# PRU_ICSSG0_PR1_ICSS_INTC_INTC_SLV_local register map
Vendor: Texas Instruments
Peripheral module from a debugger description file (folder am65x).
Registers are 32-bit, read-write, reset 0x0 unless marked. A register's access mark holds for its fields unless they carry their own. Offsets are as the file gives them; lines under a group give offsets from that group; [hi:lo] are bit positions; {n}, {i} and the like mark numbered series; 'fields as' and 'values as' point back to an identical list; <NAME> marks a mode.

## PRU_ICSSG0_PR1_ICSS_INTC_INTC_SLV
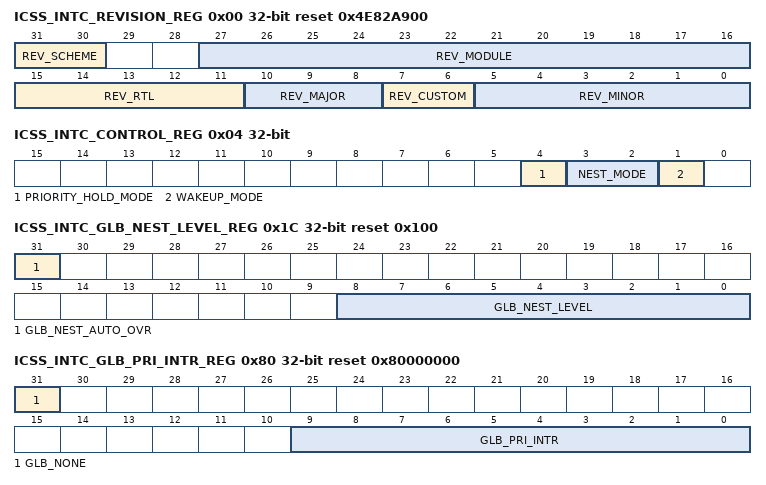
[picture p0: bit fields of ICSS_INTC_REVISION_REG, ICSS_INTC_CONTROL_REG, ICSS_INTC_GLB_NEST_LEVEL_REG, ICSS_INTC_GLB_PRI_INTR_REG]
0x00 ICSS_INTC_REVISION_REG ro reset 0x4E82A900 — Revision Register
  [31:30] REV_SCHEME — Scheme
  [27:16] REV_MODULE — Module ID
  [15:11] REV_RTL — RTL revisions
  [10:8] REV_MAJOR — Major revision
  [7:6] REV_CUSTOM — Custom revision
  [5:0] REV_MINOR — Minor revision
0x04 ICSS_INTC_CONTROL_REG — Control Register
  [4] PRIORITY_HOLD_MODE — Priority Holding Mode
  [3:2] NEST_MODE — Nesting Mode
  [1] WAKEUP_MODE — Wakeup mode enable
0x10 ICSS_INTC_GLOBAL_ENABLE_HINT_REG — Global Host Int Enable Register
  [0] ENABLE_HINT_ANY — Global Enable for all Host Ints
0x1C ICSS_INTC_GLB_NEST_LEVEL_REG access per field reset 0x100 (reset mask 0x1FF) — Global Nesting Level Register
  [31] GLB_NEST_AUTO_OVR wo — Global Nesting Level Override Automatic
  [8:0] GLB_NEST_LEVEL rw — Global Nesting Level
0x20 ICSS_INTC_STATUS_SET_INDEX_REG wo — Status Set Index Register
  [9:0] STATUS_SET_INDEX — Status Set Index Register (write index to set status of)
0x24 ICSS_INTC_STATUS_CLR_INDEX_REG wo — Status Clear Index Register
  [9:0] STATUS_CLR_INDEX — Status Clear Index Register (write index to clear status of)
0x28 ICSS_INTC_ENABLE_SET_INDEX_REG access not given — Enable Set Index Register
  [9:0] ENABLE_SET_INDEX — Enable Set Index Register (write index to set enable of) (access W1S)
0x2C ICSS_INTC_ENABLE_CLR_INDEX_REG access not given — Enable Clear Index Register
  [9:0] ENABLE_CLR_INDEX — Enable Clear Index Register (write index to clear enable of) (access W1C)
0x34 ICSS_INTC_HINT_ENABLE_SET_INDEX_REG access not given — Host Int Enable Set Index Register
  [9:0] HINT_ENABLE_SET_INDEX — Enable set for Host Interrupts (access W1S)
0x38 ICSS_INTC_HINT_ENABLE_CLR_INDEX_REG access not given — Host Int Enable Clear Index Register
  [9:0] HINT_ENABLE_CLR_INDEX — Enable clear for Host Interrupts (access W1C)
0x80 ICSS_INTC_GLB_PRI_INTR_REG ro reset 0x80000000 — Global Prioritized Interrupt Register
  [31] GLB_NONE — No interrupt pending flag
  [9:0] GLB_PRI_INTR — Prioritized Interrupt
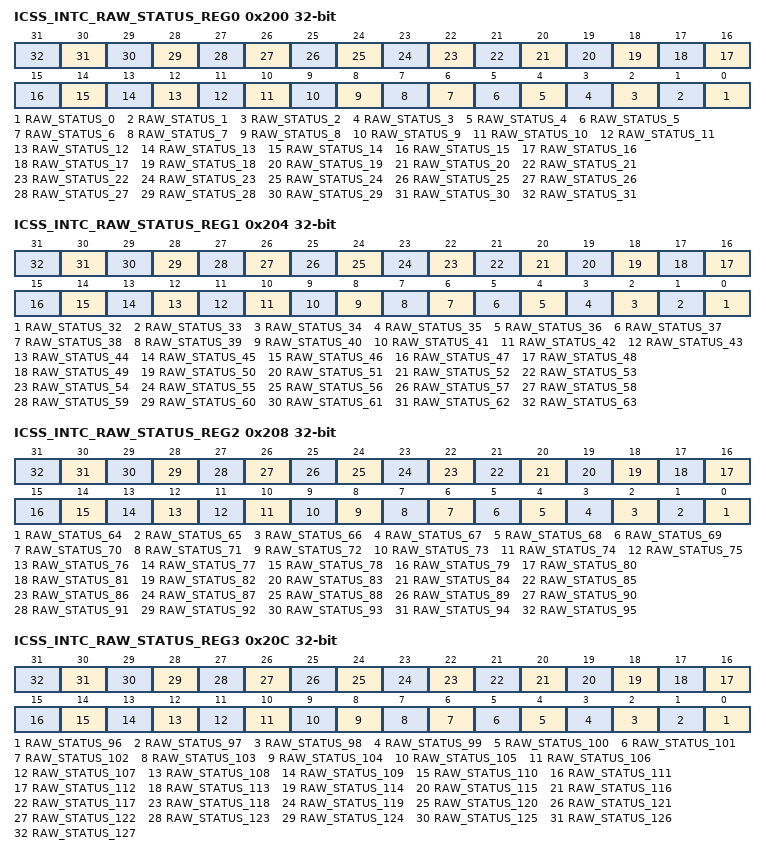
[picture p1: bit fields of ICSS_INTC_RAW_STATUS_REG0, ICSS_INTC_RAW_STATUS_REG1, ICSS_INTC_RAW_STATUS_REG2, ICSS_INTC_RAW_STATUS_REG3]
0x200 ICSS_INTC_RAW_STATUS_REG0 access not given — Raw Status Register 0
  [n] RAW_STATUS_{n} (n=0..31) — Raw Status (write 1 to set) for intr_in[{n}] (access W1S)
0x204 ICSS_INTC_RAW_STATUS_REG1 access not given — Raw Status Register 1
  [n-32] RAW_STATUS_{n} (n=32..63) — Raw Status (write 1 to set) for intr_in[{n}] (access W1S)
0x208 ICSS_INTC_RAW_STATUS_REG2 access not given — Raw Status Register 2
  [n-64] RAW_STATUS_{n} (n=64..95) — Raw Status (write 1 to set) for slv_events_in[{n-64}] (access W1S)
0x20C ICSS_INTC_RAW_STATUS_REG3 access not given — Raw Status Register 3
  [n-96] RAW_STATUS_{n} (n=96..127) — Raw Status (write 1 to set) for slv_events_in[{n-64}] (access W1S)
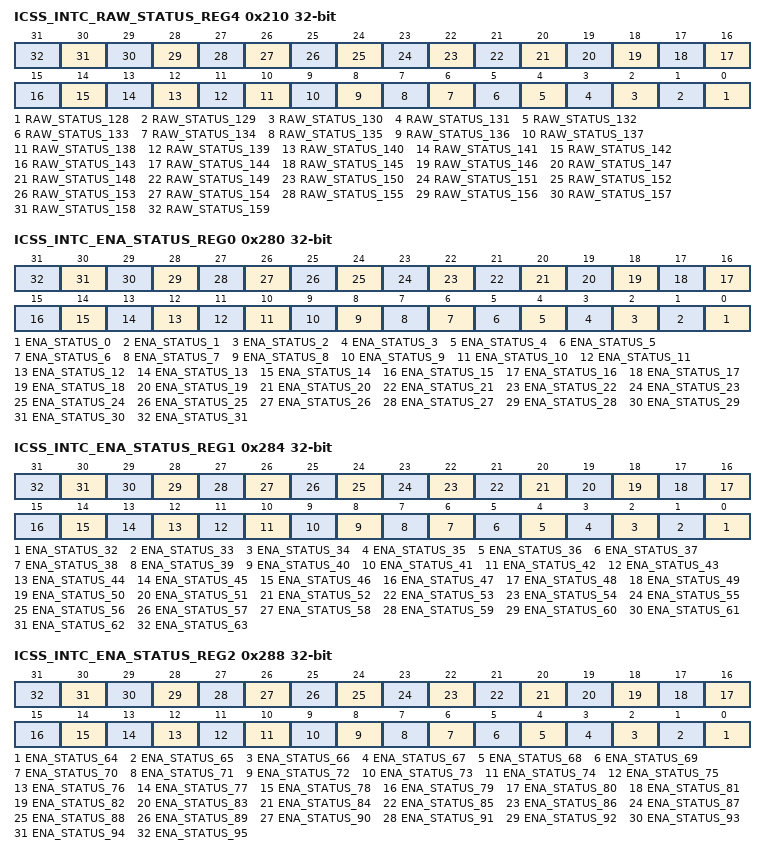
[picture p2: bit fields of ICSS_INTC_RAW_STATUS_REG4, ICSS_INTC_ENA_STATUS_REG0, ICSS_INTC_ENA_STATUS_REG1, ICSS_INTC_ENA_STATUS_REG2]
0x210 ICSS_INTC_RAW_STATUS_REG4 access not given — Raw Status Register 4
  [n-128] RAW_STATUS_{n} (n=128..159) — Raw Status (write 1 to set) for slv_events_in[{n-64}] (access W1S)
0x280 ICSS_INTC_ENA_STATUS_REG0 access not given — Enabled Status Register 0
  [n] ENA_STATUS_{n} (n=0..31) — Enabled Status for intr_in[{n}] (access W1C)
0x284 ICSS_INTC_ENA_STATUS_REG1 access not given — Enabled Status Register 1
  [n-32] ENA_STATUS_{n} (n=32..63) — Enabled Status for intr_in[{n}] (access W1C)
0x288 ICSS_INTC_ENA_STATUS_REG2 access not given — Enabled Status Register 2
  [n-64] ENA_STATUS_{n} (n=64..95) — Enabled Status for slv_events_in[{n-64}] (access W1C)
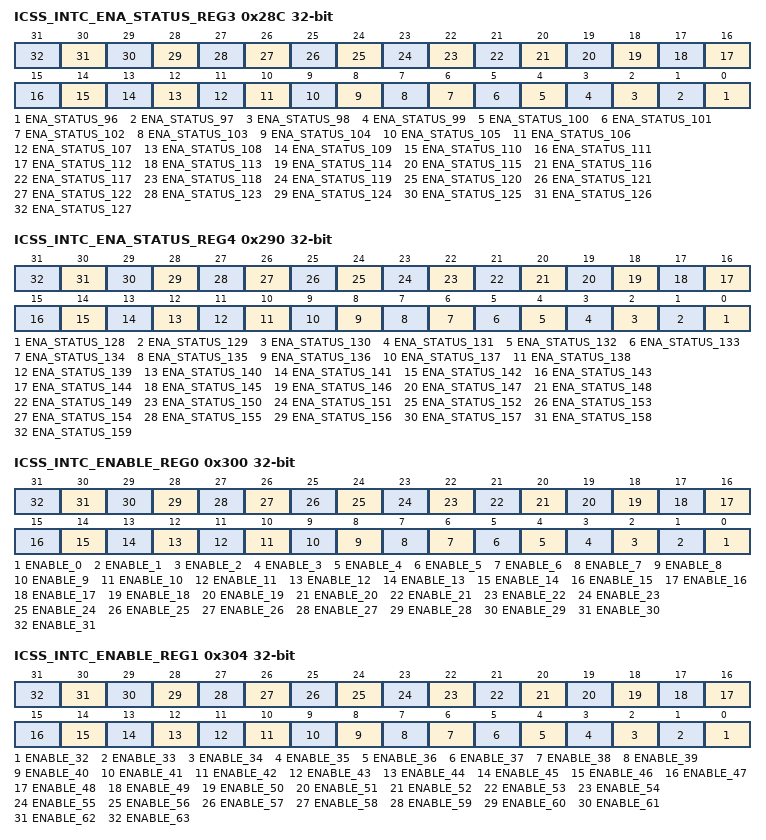
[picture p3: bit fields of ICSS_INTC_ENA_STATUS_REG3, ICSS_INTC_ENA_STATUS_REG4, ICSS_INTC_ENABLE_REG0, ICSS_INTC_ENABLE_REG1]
0x28C ICSS_INTC_ENA_STATUS_REG3 access not given — Enabled Status Register 3
  [n-96] ENA_STATUS_{n} (n=96..127) — Enabled Status for slv_events_in[{n-64}] (access W1C)
0x290 ICSS_INTC_ENA_STATUS_REG4 access not given — Enabled Status Register 4
  [n-128] ENA_STATUS_{n} (n=128..159) — Enabled Status for slv_events_in[{n-64}] (access W1C)
0x300 ICSS_INTC_ENABLE_REG0 access not given — Enable Register 0
  [n] ENABLE_{n} (n=0..31) — Enable (set) for intr_in[{n}] (access W1S)
0x304 ICSS_INTC_ENABLE_REG1 access not given — Enable Register 1
  [n-32] ENABLE_{n} (n=32..63) — Enable (set) for intr_in[{n}] (access W1S)
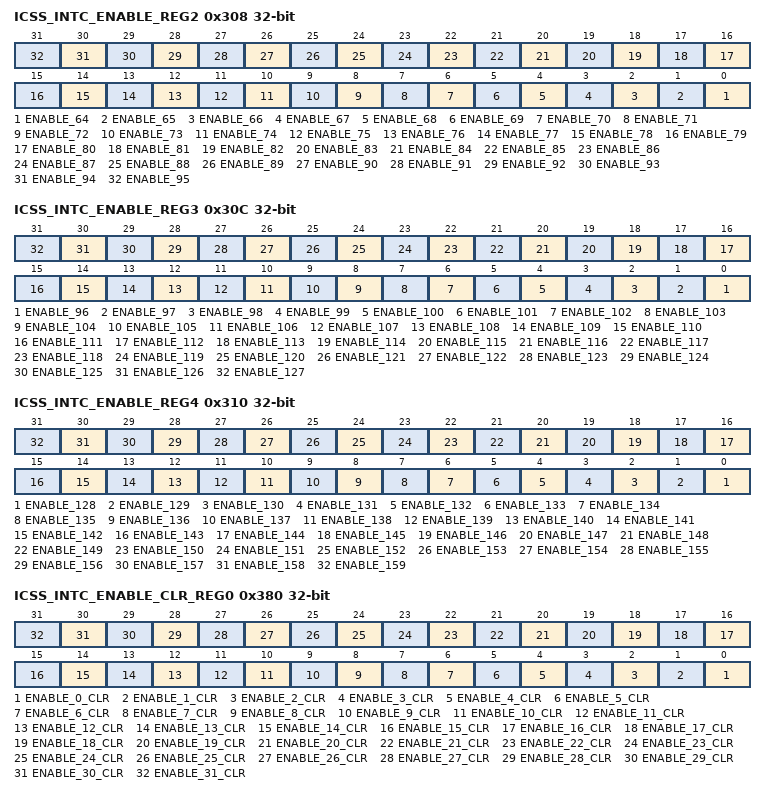
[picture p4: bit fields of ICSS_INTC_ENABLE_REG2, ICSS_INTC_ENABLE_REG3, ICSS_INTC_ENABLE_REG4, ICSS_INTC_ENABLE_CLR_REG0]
0x308 ICSS_INTC_ENABLE_REG2 access not given — Enable Register 2
  [n-64] ENABLE_{n} (n=64..95) — Enable (set) for slv_events_in[{n-64}] (access W1S)
0x30C ICSS_INTC_ENABLE_REG3 access not given — Enable Register 3
  [n-96] ENABLE_{n} (n=96..127) — Enable (set) for slv_events_in[{n-64}] (access W1S)
0x310 ICSS_INTC_ENABLE_REG4 access not given — Enable Register 4
  [n-128] ENABLE_{n} (n=128..159) — Enable (set) for slv_events_in[{n-64}] (access W1S)
0x380 ICSS_INTC_ENABLE_CLR_REG0 access not given — Enable Clear Register 0
  [n] ENABLE_{n}_CLR (n=0..31) — Enable clear for intr_in[{n}] (access W1C)
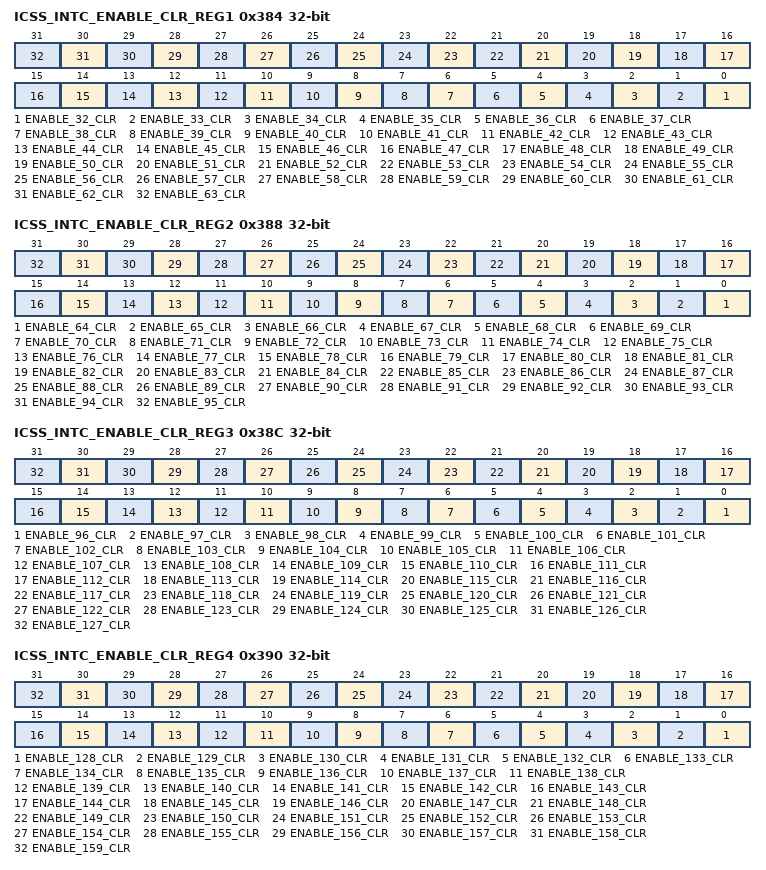
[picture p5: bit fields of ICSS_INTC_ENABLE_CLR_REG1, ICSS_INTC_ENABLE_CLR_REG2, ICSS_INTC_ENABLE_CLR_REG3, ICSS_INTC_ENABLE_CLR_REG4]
0x384 ICSS_INTC_ENABLE_CLR_REG1 access not given — Enable Clear Register 1
  [n-32] ENABLE_{n}_CLR (n=32..63) — Enable clear for intr_in[{n}] (access W1C)
0x388 ICSS_INTC_ENABLE_CLR_REG2 access not given — Enable Clear Register 2
  [n-64] ENABLE_{n}_CLR (n=64..95) — Enable clear for slv_events_in[{n-64}] (access W1C)
0x38C ICSS_INTC_ENABLE_CLR_REG3 access not given — Enable Clear Register 3
  [n-96] ENABLE_{n}_CLR (n=96..127) — Enable clear for slv_events_in[{n-64}] (access W1C)
0x390 ICSS_INTC_ENABLE_CLR_REG4 access not given — Enable Clear Register 4
  [n-128] ENABLE_{n}_CLR (n=128..159) — Enable clear for slv_events_in[{n-64}] (access W1C)
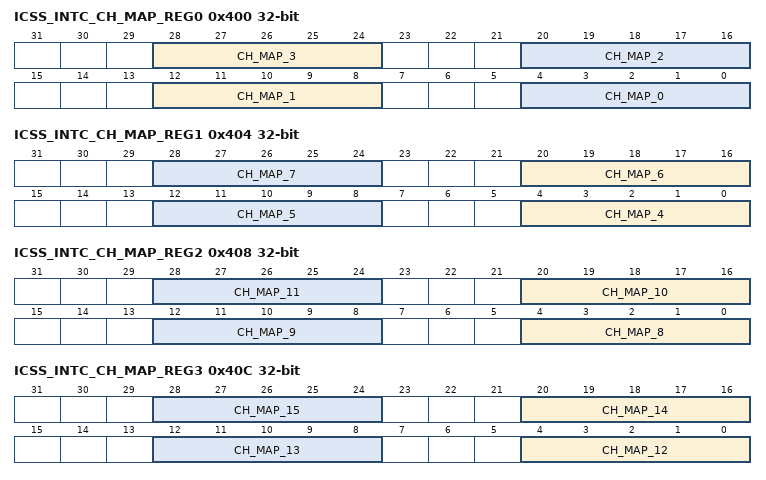
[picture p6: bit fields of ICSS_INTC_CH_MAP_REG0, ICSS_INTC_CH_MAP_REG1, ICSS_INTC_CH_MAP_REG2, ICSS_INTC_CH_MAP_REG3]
0x400 ICSS_INTC_CH_MAP_REG0 access per field — Interrupt Channel Map Register for 0 to 0+3
  [28:24] CH_MAP_3 rw — Interrupt Channel Map for intr_in[3]
  [20:16] CH_MAP_2 rw — Interrupt Channel Map for intr_in[2]
  [12:8] CH_MAP_1 rw — Interrupt Channel Map for intr_in[1]
  [4:0] CH_MAP_0 wo — Interrupt Channel Map for intr_in[0]
0x404 ICSS_INTC_CH_MAP_REG1 — Interrupt Channel Map Register for 4 to 4+3
  [8n-28:8n-32] CH_MAP_{n} (n=4..7) — Interrupt Channel Map for intr_in[{n}]
0x408 ICSS_INTC_CH_MAP_REG2 — Interrupt Channel Map Register for 8 to 8+3
  [8n-60:8n-64] CH_MAP_{n} (n=8..11) — Interrupt Channel Map for intr_in[{n}]
0x40C ICSS_INTC_CH_MAP_REG3 — Interrupt Channel Map Register for 12 to 12+3
  [8n-92:8n-96] CH_MAP_{n} (n=12..15) — Interrupt Channel Map for intr_in[{n}]
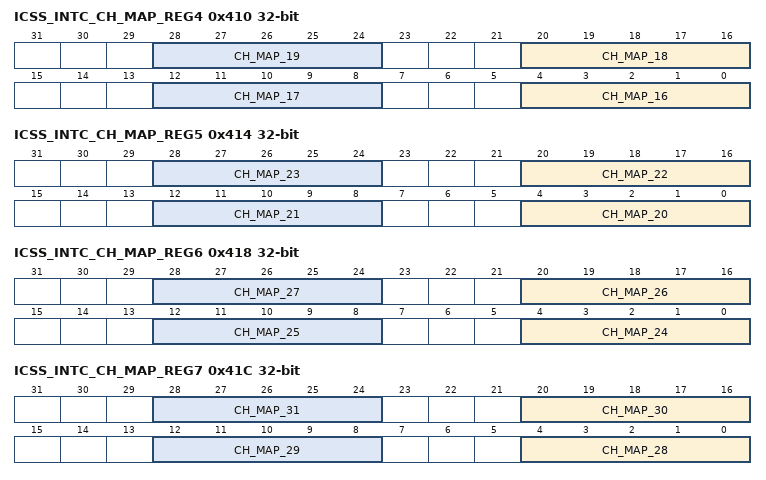
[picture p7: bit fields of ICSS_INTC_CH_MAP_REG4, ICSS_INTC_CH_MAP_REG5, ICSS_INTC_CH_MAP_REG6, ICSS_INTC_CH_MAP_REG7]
0x410 ICSS_INTC_CH_MAP_REG4 — Interrupt Channel Map Register for 16 to 16+3
  [8n-124:8n-128] CH_MAP_{n} (n=16..19) — Interrupt Channel Map for intr_in[{n}]
0x414 ICSS_INTC_CH_MAP_REG5 — Interrupt Channel Map Register for 20 to 20+3
  [8n-156:8n-160] CH_MAP_{n} (n=20..23) — Interrupt Channel Map for intr_in[{n}]
0x418 ICSS_INTC_CH_MAP_REG6 — Interrupt Channel Map Register for 24 to 24+3
  [8n-188:8n-192] CH_MAP_{n} (n=24..27) — Interrupt Channel Map for intr_in[{n}]
0x41C ICSS_INTC_CH_MAP_REG7 — Interrupt Channel Map Register for 28 to 28+3
  [8n-220:8n-224] CH_MAP_{n} (n=28..31) — Interrupt Channel Map for intr_in[{n}]
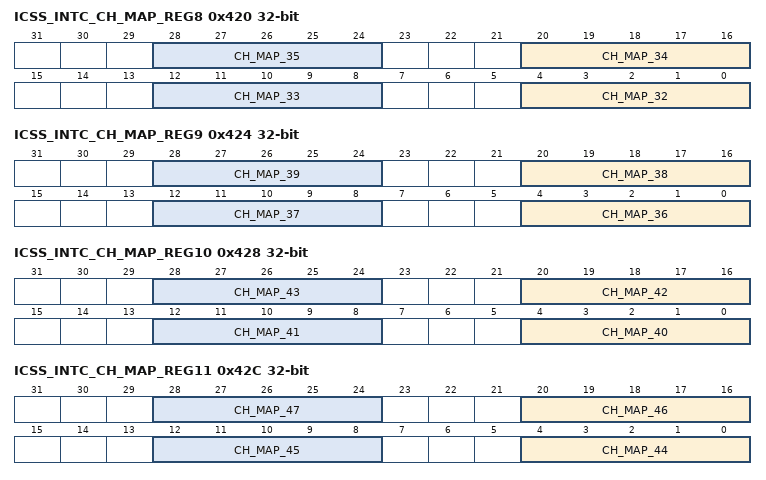
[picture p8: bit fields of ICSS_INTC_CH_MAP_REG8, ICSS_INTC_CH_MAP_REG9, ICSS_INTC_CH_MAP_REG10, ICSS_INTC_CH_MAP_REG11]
0x420 ICSS_INTC_CH_MAP_REG8 — Interrupt Channel Map Register for 32 to 32+3
  [8n-252:8n-256] CH_MAP_{n} (n=32..35) — Interrupt Channel Map for intr_in[{n}]
0x424 ICSS_INTC_CH_MAP_REG9 — Interrupt Channel Map Register for 36 to 36+3
  [8n-284:8n-288] CH_MAP_{n} (n=36..39) — Interrupt Channel Map for intr_in[{n}]
0x428 ICSS_INTC_CH_MAP_REG10 — Interrupt Channel Map Register for 40 to 40+3
  [8n-316:8n-320] CH_MAP_{n} (n=40..43) — Interrupt Channel Map for intr_in[{n}]
0x42C ICSS_INTC_CH_MAP_REG11 — Interrupt Channel Map Register for 44 to 44+3
  [8n-348:8n-352] CH_MAP_{n} (n=44..47) — Interrupt Channel Map for intr_in[{n}]
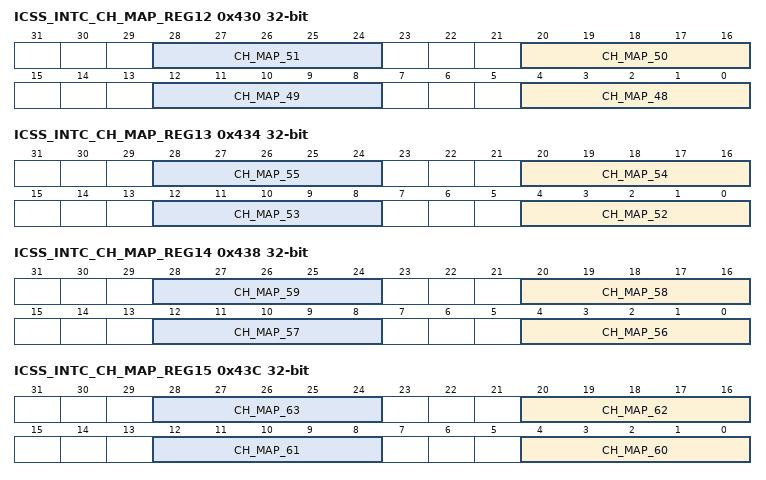
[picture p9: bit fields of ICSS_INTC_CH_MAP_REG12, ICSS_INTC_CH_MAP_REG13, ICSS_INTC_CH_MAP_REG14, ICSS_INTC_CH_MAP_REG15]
0x430 ICSS_INTC_CH_MAP_REG12 — Interrupt Channel Map Register for 48 to 48+3
  [8n-380:8n-384] CH_MAP_{n} (n=48..51) — Interrupt Channel Map for intr_in[{n}]
0x434 ICSS_INTC_CH_MAP_REG13 — Interrupt Channel Map Register for 52 to 52+3
  [8n-412:8n-416] CH_MAP_{n} (n=52..55) — Interrupt Channel Map for intr_in[{n}]
0x438 ICSS_INTC_CH_MAP_REG14 — Interrupt Channel Map Register for 56 to 56+3
  [8n-444:8n-448] CH_MAP_{n} (n=56..59) — Interrupt Channel Map for intr_in[{n}]
0x43C ICSS_INTC_CH_MAP_REG15 — Interrupt Channel Map Register for 60 to 60+3
  [8n-476:8n-480] CH_MAP_{n} (n=60..63) — Interrupt Channel Map for intr_in[{n}]
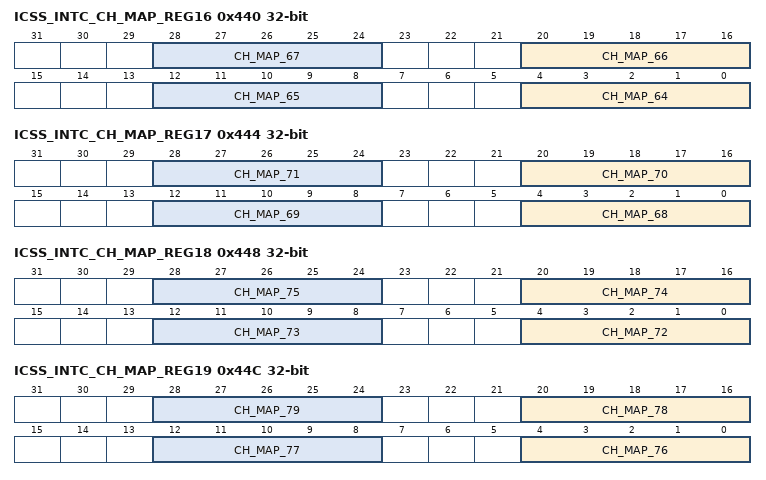
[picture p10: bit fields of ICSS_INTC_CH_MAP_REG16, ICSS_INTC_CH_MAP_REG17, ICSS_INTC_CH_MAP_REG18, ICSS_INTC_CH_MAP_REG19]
0x440 ICSS_INTC_CH_MAP_REG16 — Interrupt Channel Map Register for 64 to 64+3
  [8n-508:8n-512] CH_MAP_{n} (n=64..67) — Interrupt Channel Map for slv_events_in[{n-64}]
0x444 ICSS_INTC_CH_MAP_REG17 — Interrupt Channel Map Register for 68 to 68+3
  [8n-540:8n-544] CH_MAP_{n} (n=68..71) — Interrupt Channel Map for slv_events_in[{n-64}]
0x448 ICSS_INTC_CH_MAP_REG18 — Interrupt Channel Map Register for 72 to 72+3
  [8n-572:8n-576] CH_MAP_{n} (n=72..75) — Interrupt Channel Map for slv_events_in[{n-64}]
0x44C ICSS_INTC_CH_MAP_REG19 — Interrupt Channel Map Register for 76 to 76+3
  [8n-604:8n-608] CH_MAP_{n} (n=76..79) — Interrupt Channel Map for slv_events_in[{n-64}]
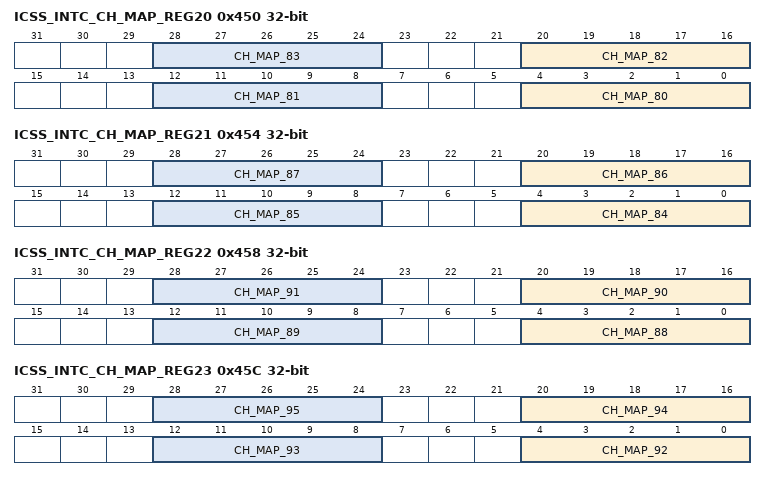
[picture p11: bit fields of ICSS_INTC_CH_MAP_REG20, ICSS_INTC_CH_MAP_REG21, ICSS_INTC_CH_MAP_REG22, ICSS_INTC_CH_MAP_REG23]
0x450 ICSS_INTC_CH_MAP_REG20 — Interrupt Channel Map Register for 80 to 80+3
  [8n-636:8n-640] CH_MAP_{n} (n=80..83) — Interrupt Channel Map for slv_events_in[{n-64}]
0x454 ICSS_INTC_CH_MAP_REG21 — Interrupt Channel Map Register for 84 to 84+3
  [8n-668:8n-672] CH_MAP_{n} (n=84..87) — Interrupt Channel Map for slv_events_in[{n-64}]
0x458 ICSS_INTC_CH_MAP_REG22 — Interrupt Channel Map Register for 88 to 88+3
  [8n-700:8n-704] CH_MAP_{n} (n=88..91) — Interrupt Channel Map for slv_events_in[{n-64}]
0x45C ICSS_INTC_CH_MAP_REG23 — Interrupt Channel Map Register for 92 to 92+3
  [8n-732:8n-736] CH_MAP_{n} (n=92..95) — Interrupt Channel Map for slv_events_in[{n-64}]
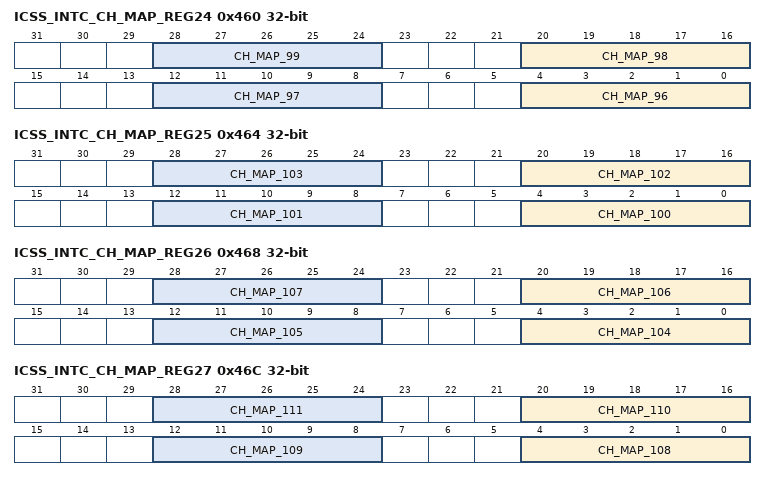
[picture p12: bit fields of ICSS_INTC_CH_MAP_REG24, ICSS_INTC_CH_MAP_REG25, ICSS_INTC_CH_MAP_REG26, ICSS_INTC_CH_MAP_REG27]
0x460 ICSS_INTC_CH_MAP_REG24 — Interrupt Channel Map Register for 96 to 96+3
  [8n-764:8n-768] CH_MAP_{n} (n=96..99) — Interrupt Channel Map for slv_events_in[{n-64}]
0x464 ICSS_INTC_CH_MAP_REG25 — Interrupt Channel Map Register for 100 to 100+3
  [8n-796:8n-800] CH_MAP_{n} (n=100..103) — Interrupt Channel Map for slv_events_in[{n-64}]
0x468 ICSS_INTC_CH_MAP_REG26 — Interrupt Channel Map Register for 104 to 104+3
  [8n-828:8n-832] CH_MAP_{n} (n=104..107) — Interrupt Channel Map for slv_events_in[{n-64}]
0x46C ICSS_INTC_CH_MAP_REG27 — Interrupt Channel Map Register for 108 to 108+3
  [8n-860:8n-864] CH_MAP_{n} (n=108..111) — Interrupt Channel Map for slv_events_in[{n-64}]
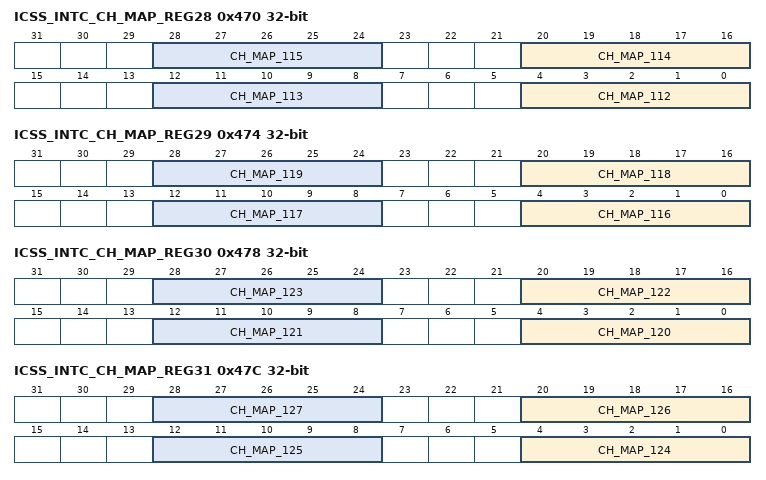
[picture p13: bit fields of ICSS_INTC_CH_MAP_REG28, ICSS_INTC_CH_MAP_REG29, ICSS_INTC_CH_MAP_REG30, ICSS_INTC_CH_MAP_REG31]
0x470 ICSS_INTC_CH_MAP_REG28 — Interrupt Channel Map Register for 112 to 112+3
  [8n-892:8n-896] CH_MAP_{n} (n=112..115) — Interrupt Channel Map for slv_events_in[{n-64}]
0x474 ICSS_INTC_CH_MAP_REG29 — Interrupt Channel Map Register for 116 to 116+3
  [8n-924:8n-928] CH_MAP_{n} (n=116..119) — Interrupt Channel Map for slv_events_in[{n-64}]
0x478 ICSS_INTC_CH_MAP_REG30 — Interrupt Channel Map Register for 120 to 120+3
  [8n-956:8n-960] CH_MAP_{n} (n=120..123) — Interrupt Channel Map for slv_events_in[{n-64}]
0x47C ICSS_INTC_CH_MAP_REG31 — Interrupt Channel Map Register for 124 to 124+3
  [8n-988:8n-992] CH_MAP_{n} (n=124..127) — Interrupt Channel Map for slv_events_in[{n-64}]
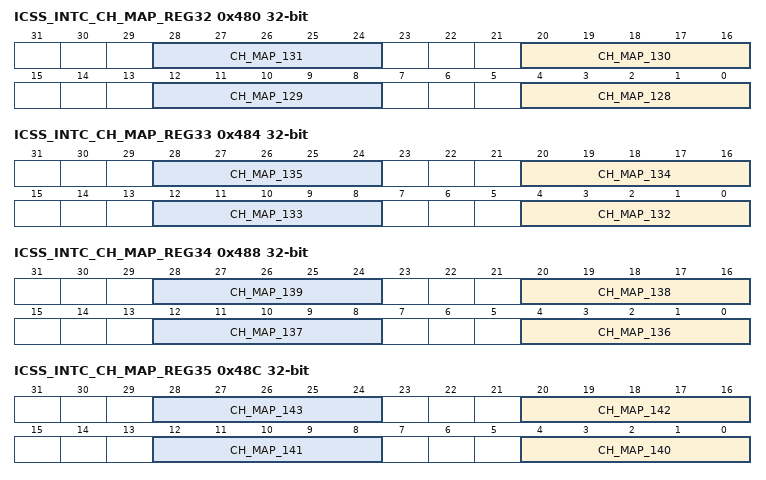
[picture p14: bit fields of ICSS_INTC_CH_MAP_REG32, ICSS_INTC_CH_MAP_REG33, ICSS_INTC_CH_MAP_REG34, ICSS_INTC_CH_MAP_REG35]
0x480 ICSS_INTC_CH_MAP_REG32 — Interrupt Channel Map Register for 128 to 128+3
  [8n-1020:8n-1024] CH_MAP_{n} (n=128..131) — Interrupt Channel Map for slv_events_in[{n-64}]
0x484 ICSS_INTC_CH_MAP_REG33 — Interrupt Channel Map Register for 132 to 132+3
  [8n-1052:8n-1056] CH_MAP_{n} (n=132..135) — Interrupt Channel Map for slv_events_in[{n-64}]
0x488 ICSS_INTC_CH_MAP_REG34 — Interrupt Channel Map Register for 136 to 136+3
  [8n-1084:8n-1088] CH_MAP_{n} (n=136..139) — Interrupt Channel Map for slv_events_in[{n-64}]
0x48C ICSS_INTC_CH_MAP_REG35 — Interrupt Channel Map Register for 140 to 140+3
  [8n-1116:8n-1120] CH_MAP_{n} (n=140..143) — Interrupt Channel Map for slv_events_in[{n-64}]
0x490 ICSS_INTC_CH_MAP_REG36 — Interrupt Channel Map Register for 144 to 144+3
  [8n-1148:8n-1152] CH_MAP_{n} (n=144..147) — Interrupt Channel Map for slv_events_in[{n-64}]
0x494 ICSS_INTC_CH_MAP_REG37 — Interrupt Channel Map Register for 148 to 148+3
  [8n-1180:8n-1184] CH_MAP_{n} (n=148..151) — Interrupt Channel Map for slv_events_in[{n-64}]
0x498 ICSS_INTC_CH_MAP_REG38 — Interrupt Channel Map Register for 152 to 152+3
  [8n-1212:8n-1216] CH_MAP_{n} (n=152..155) — Interrupt Channel Map for slv_events_in[{n-64}]
0x49C ICSS_INTC_CH_MAP_REG39 — Interrupt Channel Map Register for 156 to 156+3
  [8n-1244:8n-1248] CH_MAP_{n} (n=156..159) — Interrupt Channel Map for slv_events_in[{n-64}]
0x800 ICSS_INTC_HINT_MAP_REG0 — Host Interrupt Map Register for 0 to 0+3
  [8n+4:8n] HINT_MAP_{n} (n=0..3) — Host Interrupt Map for Channel {n}
0x804 ICSS_INTC_HINT_MAP_REG1 — Host Interrupt Map Register for 4 to 4+3
  [8n-28:8n-32] HINT_MAP_{n} (n=4..7) — Host Interrupt Map for Channel {n}
0x808 ICSS_INTC_HINT_MAP_REG2 — Host Interrupt Map Register for 8 to 8+3
  [8n-60:8n-64] HINT_MAP_{n} (n=8..11) — Host Interrupt Map for Channel {n}
0x80C ICSS_INTC_HINT_MAP_REG3 — Host Interrupt Map Register for 12 to 12+3
  [8n-92:8n-96] HINT_MAP_{n} (n=12..15) — Host Interrupt Map for Channel {n}
0x810 ICSS_INTC_HINT_MAP_REG4 — Host Interrupt Map Register for 16 to 16+4
  [8n-124:8n-128] HINT_MAP_{n} (n=16..19) — Host Interrupt Map for Channel {n}
{0x900+4i} ICSS_INTC_PRI_HINT_REG{i} ro reset 0x80000000 (i=0..19) — Host Int {i} Prioritized Interrupt Register
  [31] NONE_HINT_{i} — No interrupt pending flag
  [9:0] PRI_HINT_{i} — Host Int {i} Prioritized Interrupt
0xD00 ICSS_INTC_POLARITY_REG0 reset 0xFFFFFFFF — Polarity Register 0
  [n] POLARITY_{n} (n=0..31) — Polarity for intr_in[{n}] 0=low
0xD04 ICSS_INTC_POLARITY_REG1 reset 0xFFFFFFFF — Polarity Register 1
  [n-32] POLARITY_{n} (n=32..63) — Polarity for intr_in[{n}] 0=low
0xD08 ICSS_INTC_POLARITY_REG2 reset 0xFFFFFFFF — Polarity Register 2
  [n-64] POLARITY_{n} (n=64..95) — Polarity for slv_events_in[{n-64}] 0=low
0xD0C ICSS_INTC_POLARITY_REG3 reset 0xFFFFFFFF — Polarity Register 3
  [n-96] POLARITY_{n} (n=96..127) — Polarity for slv_events_in[{n-64}] 0=low
0xD10 ICSS_INTC_POLARITY_REG4 reset 0xFFFFFFFF — Polarity Register 4
  [n-128] POLARITY_{n} (n=128..159) — Polarity for slv_events_in[{n-64}] 0=low
0xD80 ICSS_INTC_TYPE_REG0 — Type Register 0
  [n] TYPE_{n} (n=0..31) — Type for intr_in[{n}] 0=level
0xD84 ICSS_INTC_TYPE_REG1 — Type Register 1
  [n-32] TYPE_{n} (n=32..63) — Type for intr_in[{n}] 0=level
0xD88 ICSS_INTC_TYPE_REG2 — Type Register 2
  [n-64] TYPE_{n} (n=64..95) — Type for slv_events_in[{n-64}] 0=level
0xD8C ICSS_INTC_TYPE_REG3 — Type Register 3
  [n-96] TYPE_{n} (n=96..127) — Type for slv_events_in[{n-64}] 0=level
0xD90 ICSS_INTC_TYPE_REG4 — Type Register 4
  [n-128] TYPE_{n} (n=128..159) — Type for slv_events_in[{n-64}] 0=level
{0x1100+4i} ICSS_INTC_NEST_LEVEL_REG{i} access per field reset 0x100 (reset mask 0x1FF) (i=0..11) — Host Int {i} Nesting Level Register
  [31] NEST_AUTO_OVR wo — Nesting Level Override Automatic
  [8:0] NEST_HINT_{i} rw — Host Int {i} Nesting Level
{0x1100+4i} ICSS_INTC_NEST_LEVEL_REG{i} access per field reset 0x100 (reset mask 0x1FF) (i=12..19) — Host Int 11 Nesting Level Register
  fields as ICSS_INTC_NEST_LEVEL_REG0
0x1500 ICSS_INTC_ENABLE_HINT_REG0 — Host Int Enable Register 0
  [n] ENABLE_HINT_{n} (n=0..19) — Enable for Host Int {n}
